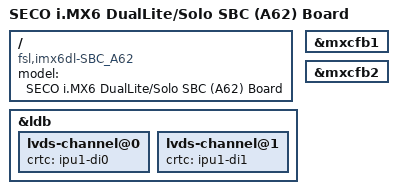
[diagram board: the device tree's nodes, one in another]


/dts-v1/;

#include "imx6dl.dtsi"
#include "imx6qdl-seco_SBC_A62_board.dtsi"
#include "imx6qdl-seco_lvds_display.dtsi"


/ {
	model = "SECO i.MX6 DualLite/Solo SBC (A62) Board";
	compatible = "fsl,imx6dl-SBC_A62", "fsl,imx6dl";
};



&ldb {
	lvds-channel@0 {
		crtc = "ipu1-di0";
	};

	lvds-channel@1 {
		crtc = "ipu1-di1";
	};
};


&mxcfb1 {
	status = "okay";
};

&mxcfb2 {
	status = "okay";
};
